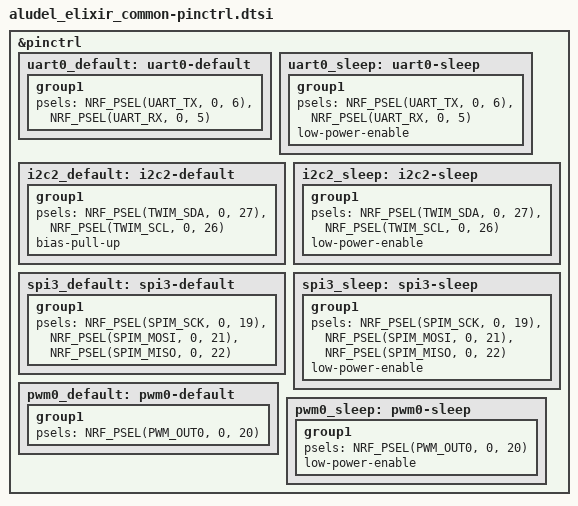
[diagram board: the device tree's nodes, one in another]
/*
 * Copyright (c) 2022 Nordic Semiconductor
 * Copyright (c) 2024 Golioth, Inc.
 * SPDX-License-Identifier: Apache-2.0
 */

&pinctrl {
	/* UART pins connected to the USB-to-UART converter */
	uart0_default: uart0-default {
		group1 {
			psels = <NRF_PSEL(UART_TX, 0, 6)>,
				<NRF_PSEL(UART_RX, 0, 5)>;
		};
	};

	uart0_sleep: uart0-sleep {
		group1 {
			psels = <NRF_PSEL(UART_TX, 0, 6)>,
				<NRF_PSEL(UART_RX, 0, 5)>;
			low-power-enable;
		};
	};

	/* I2C pins connected to the onboard I2C devices, QWIIC connectors, and
	 * mikroBUS headers.
	 */
	i2c2_default: i2c2-default {
		group1 {
			psels = <NRF_PSEL(TWIM_SDA, 0, 27)>,
				<NRF_PSEL(TWIM_SCL, 0, 26)>;
			bias-pull-up;
		};
	};

	i2c2_sleep: i2c2-sleep {
		group1 {
			psels = <NRF_PSEL(TWIM_SDA, 0, 27)>,
				<NRF_PSEL(TWIM_SCL, 0, 26)>;
			low-power-enable;
		};
	};

	/* SPI pins connected to the mikroBUS headers (and external NOR flash on rev B) */
	spi3_default: spi3-default {
		group1 {
			psels = <NRF_PSEL(SPIM_SCK, 0, 19)>,
			        <NRF_PSEL(SPIM_MOSI, 0, 21)>,
			        <NRF_PSEL(SPIM_MISO, 0, 22)>;
		};
	};

	spi3_sleep: spi3-sleep {
		group1 {
			psels = <NRF_PSEL(SPIM_SCK, 0, 19)>,
			        <NRF_PSEL(SPIM_MOSI, 0, 21)>,
			        <NRF_PSEL(SPIM_MISO, 0, 22)>;
			low-power-enable;
		};
	};

	/* PWM pin connected to the buzzer */
	pwm0_default: pwm0-default {
		group1 {
			psels = <NRF_PSEL(PWM_OUT0, 0, 20)>;
		};
	};

	pwm0_sleep: pwm0-sleep {
		group1 {
			psels = <NRF_PSEL(PWM_OUT0, 0, 20)>;
			low-power-enable;
		};
	};
};
